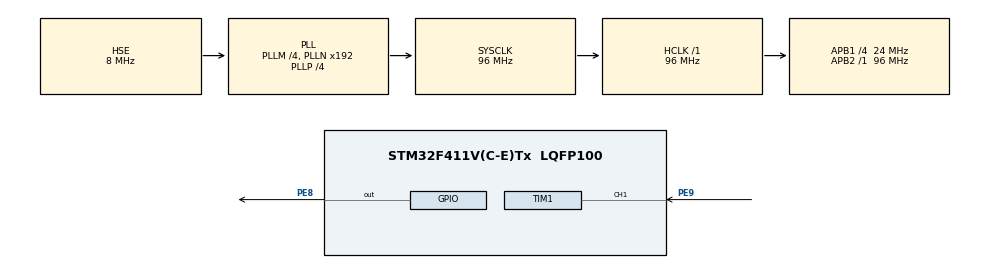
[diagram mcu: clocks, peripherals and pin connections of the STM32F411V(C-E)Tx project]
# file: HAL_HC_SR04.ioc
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Mcu.Family=STM32F4
Mcu.Name=STM32F411V(C-E)Tx
Mcu.Package=LQFP100
NVIC.PriorityGroup=NVIC_PRIORITYGROUP_0
NVIC.TIM1_CC_IRQn=true\:0\:0\:false\:false\:true\:true\:true\:true
PA13.Mode=Serial_Wire
PA13.Signal=SYS_JTMS-SWDIO
PA14.Mode=Serial_Wire
PA14.Signal=SYS_JTCK-SWCLK
PE8.Signal=GPIO_Output
PE9.Signal=S_TIM1_CH1
PH0\ -\ OSC_IN.Mode=HSE-External-Oscillator
PH0\ -\ OSC_IN.Signal=RCC_OSC_IN
PH1\ -\ OSC_OUT.Mode=HSE-External-Oscillator
PH1\ -\ OSC_OUT.Signal=RCC_OSC_OUT
ProjectManager.HeapSize=0x200
ProjectManager.StackSize=0x400
ProjectManager.TargetToolchain=STM32CubeIDE
RCC.48MHZClocksFreq_Value=48000000
RCC.AHBFreq_Value=96000000
RCC.APB1CLKDivider=RCC_HCLK_DIV4
RCC.APB1Freq_Value=24000000
RCC.APB1TimFreq_Value=48000000
RCC.APB2Freq_Value=96000000
RCC.APB2TimFreq_Value=96000000
RCC.CortexFreq_Value=96000000
RCC.HCLKFreq_Value=96000000
RCC.HSE_VALUE=8000000
RCC.HSI_VALUE=16000000
RCC.PLLI2SM=5
RCC.PLLI2SN=200
RCC.PLLM=4
RCC.PLLP=RCC_PLLP_DIV4
RCC.PLLQ=8
RCC.PLLSourceVirtual=RCC_PLLSOURCE_HSE
RCC.SYSCLKFreq_VALUE=96000000
RCC.SYSCLKSource=RCC_SYSCLKSOURCE_PLLCLK
RCC.VCOOutputFreq_Value=384000000
SH.S_TIM1_CH1.0=TIM1_CH1,Input_Capture1_from_TI1
TIM1.Channel-Input_Capture1_from_TI1=TIM_CHANNEL_1
TIM1.Prescaler=95
board=STM32F411E-DISCO

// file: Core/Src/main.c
/* USER CODE BEGIN Header */
/**
  ******************************************************************************
  * @file           : main.c
  * @brief          : Main program body
  ******************************************************************************
  * @attention
  *
  * Copyright (c) 2022 STMicroelectronics.
  * All rights reserved.
  *
  * This software is licensed under terms that can be found in the LICENSE file
  * in the root directory of this software component.
  * If no LICENSE file comes with this software, it is provided AS-IS.
  *
  ******************************************************************************
  */
/* USER CODE END Header */
#include "main.h"

 TIM_HandleTypeDef htim1;

/* USER CODE BEGIN PV */
uint32_t IC_Val1 = 0;
uint32_t IC_Val2 = 0;
uint32_t Difference = 0;
uint8_t Is_First_Captured = 0;
float Distance = 0;
float sum;
uint8_t cnt=0;
float avg=0;

#define TRIG_PIN GPIO_PIN_8
#define TRIG_PORT GPIOE
/* USER CODE END PV */

void SystemClock_Config(void);
static void MX_GPIO_Init(void);
static void MX_TIM1_Init(void);
/* USER CODE BEGIN PFP */
void delay(uint16_t time);
void HCSR04_Read (void);
//void HAL_TIM_IC_CaptureCallback(TIM_HandleTypeDef *htim);
/* USER CODE END PFP */

int main(void)
{

  /* MCU Configuration--------------------------------------------------------*/

  /* Reset of all peripherals, Initializes the Flash interface and the Systick. */
  HAL_Init();

  /* Configure the system clock */
  SystemClock_Config();

  /* Initialize all configured peripherals */
  MX_GPIO_Init();
  MX_TIM1_Init();
  /* USER CODE BEGIN 2 */
  HAL_TIM_IC_Start_IT(&htim1, TIM_CHANNEL_1);
  /* USER CODE END 2 */

  /* Infinite loop */
  while (1)
  {

    /* USER CODE BEGIN 3 */
	  HCSR04_Read();
	  HAL_Delay(10);
  }
  /* USER CODE END 3 */
}

void SystemClock_Config(void)
{
  RCC_OscInitTypeDef RCC_OscInitStruct = {0};
  RCC_ClkInitTypeDef RCC_ClkInitStruct = {0};

  /** Configure the main internal regulator output voltage
  */
  __HAL_RCC_PWR_CLK_ENABLE();
  __HAL_PWR_VOLTAGESCALING_CONFIG(PWR_REGULATOR_VOLTAGE_SCALE1);

  /** Initializes the RCC Oscillators according to the specified parameters
  * in the RCC_OscInitTypeDef structure.
  */
  RCC_OscInitStruct.OscillatorType = RCC_OSCILLATORTYPE_HSE;
  RCC_OscInitStruct.HSEState = RCC_HSE_ON;
  RCC_OscInitStruct.PLL.PLLState = RCC_PLL_ON;
  RCC_OscInitStruct.PLL.PLLSource = RCC_PLLSOURCE_HSE;
  RCC_OscInitStruct.PLL.PLLM = 4;
  RCC_OscInitStruct.PLL.PLLN = 192;
  RCC_OscInitStruct.PLL.PLLP = RCC_PLLP_DIV4;
  RCC_OscInitStruct.PLL.PLLQ = 8;
  if (HAL_RCC_OscConfig(&RCC_OscInitStruct) != HAL_OK)
  {
    Error_Handler();
  }

  /** Initializes the CPU, AHB and APB buses clocks
  */
  RCC_ClkInitStruct.ClockType = RCC_CLOCKTYPE_HCLK|RCC_CLOCKTYPE_SYSCLK
                              |RCC_CLOCKTYPE_PCLK1|RCC_CLOCKTYPE_PCLK2;
  RCC_ClkInitStruct.SYSCLKSource = RCC_SYSCLKSOURCE_PLLCLK;
  RCC_ClkInitStruct.AHBCLKDivider = RCC_SYSCLK_DIV1;
  RCC_ClkInitStruct.APB1CLKDivider = RCC_HCLK_DIV4;
  RCC_ClkInitStruct.APB2CLKDivider = RCC_HCLK_DIV1;

  if (HAL_RCC_ClockConfig(&RCC_ClkInitStruct, FLASH_LATENCY_3) != HAL_OK)
  {
    Error_Handler();
  }
}

static void MX_TIM1_Init(void)
{

  TIM_MasterConfigTypeDef sMasterConfig = {0};
  TIM_IC_InitTypeDef sConfigIC = {0};

  htim1.Instance = TIM1;
  htim1.Init.Prescaler = 95;
  htim1.Init.CounterMode = TIM_COUNTERMODE_UP;
  htim1.Init.Period = 65535;
  htim1.Init.ClockDivision = TIM_CLOCKDIVISION_DIV1;
  htim1.Init.RepetitionCounter = 0;
  htim1.Init.AutoReloadPreload = TIM_AUTORELOAD_PRELOAD_ENABLE;
  if (HAL_TIM_IC_Init(&htim1) != HAL_OK)
  {
    Error_Handler();
  }
  sMasterConfig.MasterOutputTrigger = TIM_TRGO_RESET;
  sMasterConfig.MasterSlaveMode = TIM_MASTERSLAVEMODE_DISABLE;
  if (HAL_TIMEx_MasterConfigSynchronization(&htim1, &sMasterConfig) != HAL_OK)
  {
    Error_Handler();
  }
  sConfigIC.ICPolarity = TIM_INPUTCHANNELPOLARITY_RISING;
  sConfigIC.ICSelection = TIM_ICSELECTION_DIRECTTI;
  sConfigIC.ICPrescaler = TIM_ICPSC_DIV1;
  sConfigIC.ICFilter = 0;
  if (HAL_TIM_IC_ConfigChannel(&htim1, &sConfigIC, TIM_CHANNEL_1) != HAL_OK)
  {
    Error_Handler();
  }

}

static void MX_GPIO_Init(void)
{
  GPIO_InitTypeDef GPIO_InitStruct = {0};

  /* GPIO Ports Clock Enable */
  __HAL_RCC_GPIOH_CLK_ENABLE();
  __HAL_RCC_GPIOE_CLK_ENABLE();
  __HAL_RCC_GPIOA_CLK_ENABLE();

  /*Configure GPIO pin Output Level */
  HAL_GPIO_WritePin(GPIOE, GPIO_PIN_8, GPIO_PIN_RESET);

  /*Configure GPIO pin : PE8 */
  GPIO_InitStruct.Pin = GPIO_PIN_8;
  GPIO_InitStruct.Mode = GPIO_MODE_OUTPUT_PP;
  GPIO_InitStruct.Pull = GPIO_NOPULL;
  GPIO_InitStruct.Speed = GPIO_SPEED_FREQ_LOW;
  HAL_GPIO_Init(GPIOE, &GPIO_InitStruct);

}

/* USER CODE BEGIN 4 */

void delay(uint16_t time)
{
	__HAL_TIM_SET_COUNTER(&htim1, 0);
	while(__HAL_TIM_GET_COUNTER(&htim1)<time){}
}

void HCSR04_Read (void)
{
	HAL_GPIO_WritePin(TRIG_PORT, TRIG_PIN, GPIO_PIN_SET);
	delay(10);
	HAL_GPIO_WritePin(TRIG_PORT, TRIG_PIN, GPIO_PIN_RESET);

	__HAL_TIM_ENABLE_IT(&htim1,TIM_IT_CC1);
}

void HAL_TIM_IC_CaptureCallback(TIM_HandleTypeDef *htim)
{

	if(htim->Channel == HAL_TIM_ACTIVE_CHANNEL_1)	// If the interrupt source is channel 1
	{
		if(Is_First_Captured==0)					// id the first value is not captured
		{
			IC_Val1=HAL_TIM_ReadCapturedValue(htim, TIM_CHANNEL_1);		//read the first value
			Is_First_Captured = 1;					// set first captured as true
			// Now change the polarity to falling edge
			__HAL_TIM_SET_CAPTUREPOLARITY(htim,TIM_CHANNEL_1,TIM_INPUTCHANNELPOLARITY_FALLING);
		}

		else if(Is_First_Captured==1)
		{
			IC_Val2 = HAL_TIM_ReadCapturedValue(htim, TIM_CHANNEL_1);	// read second valve
			__HAL_TIM_SET_COUNTER(htim,0);								// reset the counter
			if(IC_Val2 > IC_Val1)
			{
				Difference = IC_Val2-IC_Val1;
			}

			else if (IC_Val1 > IC_Val2)
			{
				Difference = (0 - IC_Val1) + IC_Val2;
			}

			Distance = Difference * .034/2;

			if(cnt<4) {	sum+=Distance; cnt++; }
			else { avg=sum/4; sum=0; cnt=0; }

			Is_First_Captured =0;	// set it back to false

			__HAL_TIM_SET_CAPTUREPOLARITY(htim,TIM_CHANNEL_1,TIM_INPUTCHANNELPOLARITY_RISING);
			__HAL_TIM_DISABLE_IT(&htim1, TIM_IT_CC1);
		}
	}
}
/* USER CODE END 4 */

void Error_Handler(void)
{
  __disable_irq();
  while (1)
  {
  }
}
